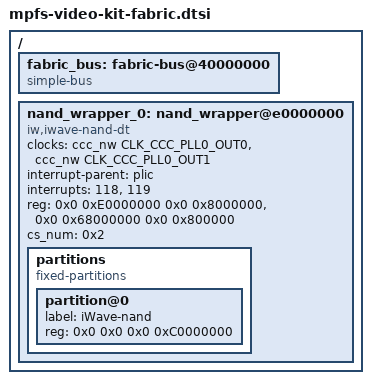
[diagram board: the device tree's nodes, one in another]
// SPDX-License-Identifier: (GPL-2.0 OR MIT)
/* Copyright (c) 2022 Microchip Technology Inc */

/ {

	fabric_bus: fabric-bus@40000000 {
		compatible = "simple-bus";
		#address-cells = <2>;
		#size-cells = <2>;
		ranges = <0x0 0x40000000 0x0 0x40000000 0x0 0x20000000>, /* FIC3-FAB */
			 <0x0 0x60000000 0x0 0x60000000 0x0 0x20000000>, /* FIC0, LO */
			 <0x0 0xe0000000 0x0 0xe0000000 0x0 0x20000000>, /* FIC1, LO */
			 <0x20 0x0 0x20 0x0 0x10 0x0>, /* FIC0,HI */
			 <0x30 0x0 0x30 0x0 0x10 0x0>; /* FIC1,HI */
	};
	nand_wrapper_0: nand_wrapper@e0000000 {
		#address-cells = <0x2>;
		#size-cells = <0x2>;
		clock-names = "s_aclk", "host_clk";
		clocks = <&ccc_nw CLK_CCC_PLL0_OUT0>, <&ccc_nw CLK_CCC_PLL0_OUT1>;
		compatible = "iw,iwave-nand-dt";
		interrupt-names = "ecc_irq", "data_irq";
		interrupt-parent = <&plic>;
		#interrupt-cells = <2>;
		interrupts = <118>, <119>;
		reg = <0x0 0xE0000000 0x0 0x8000000>, <0x0 0x68000000 0x0 0x800000>;
		reg-names = "nand_data", "nand_reg";
		status = "okay";
		cs_num = <0x2>;
		partitions {
			compatible = "fixed-partitions";
			#address-cells = <0x2>;
			#size-cells = <0x2>;
			partition@0 { /* for testing purpose */
				label = "iWave-nand";
				reg = <0x0 0x0 0x0 0xC0000000>;
			};
		};
	};
};

